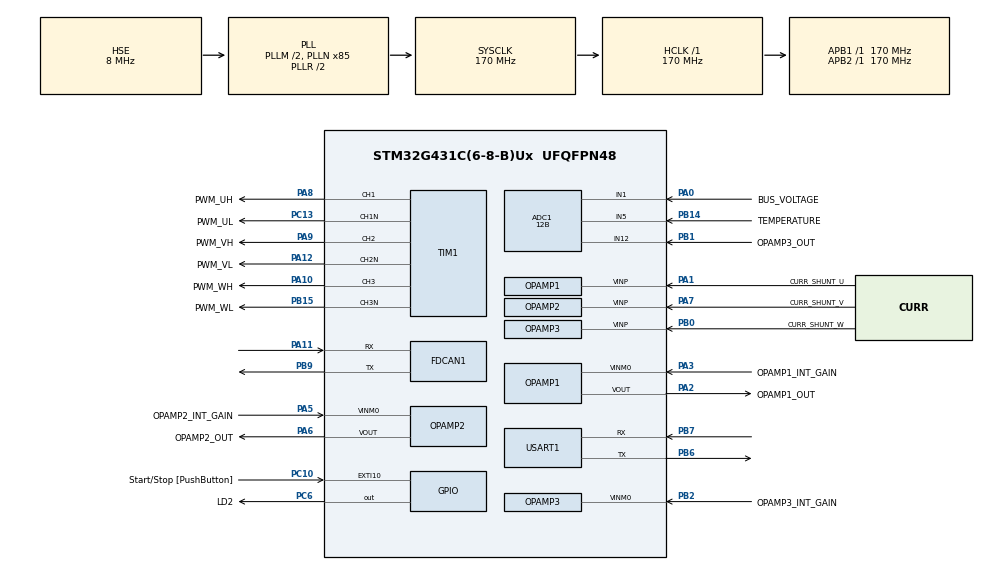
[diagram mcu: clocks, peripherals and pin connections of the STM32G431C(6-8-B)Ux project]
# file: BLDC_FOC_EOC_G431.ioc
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ADC1.Channel-1\#ChannelRegularConversion=ADC_CHANNEL_1
ADC1.Channel-2\#ChannelRegularConversion=ADC_CHANNEL_5
ADC1.ClockPrescaler=ADC_CLOCK_ASYNC_DIV1
ADC1.ContinuousConvMode=DISABLE
ADC1.DMAContinuousRequests=DISABLE
ADC1.DataAlign=ADC_DATAALIGN_LEFT
ADC1.DiscontinuousConvMode=DISABLE
ADC1.EOCSelection=ADC_EOC_SINGLE_CONV
ADC1.EnableAnalogWatchDog1=false
ADC1.EnableAnalogWatchDog2=false
ADC1.EnableAnalogWatchDog3=false
ADC1.EnableInjectedConversion=ENABLE
ADC1.EnableRegularConversion=ENABLE
ADC1.ExternalTrigConv=ADC_SOFTWARE_START
ADC1.ExternalTrigConvEdge=ADC_EXTERNALTRIGCONVEDGE_NONE
ADC1.ExternalTrigInjecConv=ADC_EXTERNALTRIGINJEC_T1_CC4
ADC1.ExternalTrigInjecConvEdge=ADC_EXTERNALTRIGINJECCONV_EDGE_RISING
ADC1.InjNumberOfConversion=2
ADC1.InjectedChannel-1\#ChannelInjectedConversion=ADC_CHANNEL_3
ADC1.InjectedChannel-2\#ChannelInjectedConversion=ADC_CHANNEL_12
ADC1.InjectedConvMode=None
ADC1.InjectedOffset-1\#ChannelInjectedConversion=0
ADC1.InjectedOffset-2\#ChannelInjectedConversion=0
ADC1.InjectedOffsetNumber-1\#ChannelInjectedConversion=ADC_OFFSET_NONE
ADC1.InjectedOffsetNumber-2\#ChannelInjectedConversion=ADC_OFFSET_NONE
ADC1.InjectedRank-1\#ChannelInjectedConversion=1
ADC1.InjectedRank-2\#ChannelInjectedConversion=2
ADC1.InjectedSamplingTime-1\#ChannelInjectedConversion=ADC_SAMPLETIME_6CYCLES_5
ADC1.InjectedSamplingTime-2\#ChannelInjectedConversion=ADC_SAMPLETIME_6CYCLES_5
ADC1.LowPowerAutoWait=DISABLE
ADC1.NbrOfConversion=2
ADC1.NbrOfConversionFlag=1
ADC1.Offset-1\#ChannelRegularConversion=0
ADC1.Offset-2\#ChannelRegularConversion=0
ADC1.OffsetNumber-1\#ChannelRegularConversion=ADC_OFFSET_NONE
ADC1.OffsetNumber-2\#ChannelRegularConversion=ADC_OFFSET_NONE
ADC1.Overrun=ADC_OVR_DATA_PRESERVED
ADC1.Rank-1\#ChannelRegularConversion=1
ADC1.Rank-2\#ChannelRegularConversion=2
ADC1.Resolution=ADC_RESOLUTION_12B
ADC1.SamplingTime-1\#ChannelRegularConversion=ADC_SAMPLETIME_47CYCLES_5
ADC1.SamplingTime-2\#ChannelRegularConversion=ADC_SAMPLETIME_47CYCLES_5
ADC1.ScanConvMode=ADC_SCAN_ENABLE
ADC1.master=1
ADC2.ClockPrescaler=ADC_CLOCK_ASYNC_DIV1
ADC2.ContinuousConvMode=DISABLE
ADC2.DMAContinuousRequests=DISABLE
ADC2.DataAlign=ADC_DATAALIGN_LEFT
ADC2.DiscontinuousConvMode=DISABLE
ADC2.EOCSelection=ADC_EOC_SINGLE_CONV
ADC2.EnableAnalogWatchDog1=false
ADC2.EnableAnalogWatchDog2=false
ADC2.EnableAnalogWatchDog3=false
ADC2.EnableInjectedConversion=ENABLE
ADC2.EnableRegularConversion=DISABLE
ADC2.ExternalTrigInjecConv=ADC_EXTERNALTRIGINJEC_T1_CC4
ADC2.ExternalTrigInjecConvEdge=ADC_EXTERNALTRIGINJECCONV_EDGE_RISING
ADC2.InjNumberOfConversion=2
ADC2.InjectedChannel-1\#ChannelInjectedConversion=ADC_CHANNEL_VOPAMP3_ADC2
ADC2.InjectedChannel-2\#ChannelInjectedConversion=ADC_CHANNEL_3
ADC2.InjectedConvMode=None
ADC2.InjectedOffset-1\#ChannelInjectedConversion=0
ADC2.InjectedOffset-2\#ChannelInjectedConversion=0
ADC2.InjectedOffsetNumber-1\#ChannelInjectedConversion=ADC_OFFSET_NONE
ADC2.InjectedOffsetNumber-2\#ChannelInjectedConversion=ADC_OFFSET_NONE
ADC2.InjectedRank-1\#ChannelInjectedConversion=1
ADC2.InjectedRank-2\#ChannelInjectedConversion=2
ADC2.InjectedSamplingTime-1\#ChannelInjectedConversion=ADC_SAMPLETIME_6CYCLES_5
ADC2.InjectedSamplingTime-2\#ChannelInjectedConversion=ADC_SAMPLETIME_6CYCLES_5
ADC2.LowPowerAutoWait=DISABLE
ADC2.Overrun=ADC_OVR_DATA_PRESERVED
ADC2.Resolution=ADC_RESOLUTION_12B
ADC2.ScanConvMode=ADC_SCAN_ENABLE
ADC2.master=1
FDCAN1.CalculateBaudRateNominal=1000000
FDCAN1.CalculateTimeBitNominal=1000
FDCAN1.CalculateTimeQuantumNominal=100.0
FDCAN1.NominalPrescaler=17
FDCAN1.NominalTimeSeg1=7
FDCAN1.NominalTimeSeg2=2
Mcu.Family=STM32G4
Mcu.Name=STM32G431C(6-8-B)Ux
Mcu.Package=UFQFPN48
NVIC.ADC1_2_IRQn=true\:2\:0\:true\:true\:false\:3\:true\:true\:true
NVIC.EXTI15_10_IRQn=true\:3\:0\:false\:true\:false\:4\:true\:true\:true
NVIC.FDCAN1_IT0_IRQn=true\:0\:0\:false\:false\:true\:true\:true\:true
NVIC.PriorityGroup=NVIC_PRIORITYGROUP_3
NVIC.TIM1_BRK_TIM15_IRQn=true\:4\:1\:true\:true\:false\:1\:true\:true\:true
NVIC.TIM1_UP_TIM16_IRQn=true\:0\:0\:false\:true\:false\:2\:true\:true\:true
NVIC.USART1_IRQn=true\:5\:0\:true\:false\:true\:true\:true\:true
OPAMP1.PgaGain=OPAMP_PGA_GAIN_16_OR_MINUS_15
OPAMP1.SelfCalibration=Disable
OPAMP2.PgaGain=OPAMP_PGA_GAIN_16_OR_MINUS_15
OPAMP2.SelfCalibration=Disable
OPAMP3.PgaGain=OPAMP_PGA_GAIN_16_OR_MINUS_15
OPAMP3.SelfCalibration=Disable
PA0.GPIO_Label=BUS_VOLTAGE
PA0.Mode=IN1-Single-Ended
PA0.Signal=ADC1_IN1
PA1.GPIO_Label=CURR_SHUNT_U
PA1.Mode=PGA Connected-INVERTINGINPUT_IO0_BIAS
PA1.Signal=OPAMP1_VINP
PA10.GPIO_Label=PWM_WH
PA10.GPIO_PuPd=GPIO_PULLDOWN
PA10.GPIO_Speed=GPIO_SPEED_FREQ_HIGH
PA10.Signal=S_TIM1_CH3
PA11.Mode=FDCAN_Activate
PA11.Signal=FDCAN1_RX
PA12.GPIO_Label=PWM_VL
PA12.GPIO_PuPd=GPIO_PULLDOWN
PA12.GPIO_Speed=GPIO_SPEED_FREQ_HIGH
PA12.Mode=PWM Generation2 CH2 CH2N
PA12.Signal=TIM1_CH2N
PA13.GPIO_Label=TMS
PA13.Mode=Serial_Wire
PA13.Signal=SYS_JTMS-SWDIO
PA14.GPIO_Label=TCK
PA14.Mode=Serial_Wire
PA14.Signal=SYS_JTCK-SWCLK
PA2.GPIO_Label=OPAMP1_OUT
PA2.Signal=SharedAnalog_PA2
PA3.GPIO_Label=OPAMP1_INT_GAIN
PA3.Mode=PGA Connected-INVERTINGINPUT_IO0_BIAS
PA3.Signal=OPAMP1_VINM0
PA5.GPIO_Label=OPAMP2_INT_GAIN
PA5.Mode=PGA Connected-INVERTINGINPUT_IO0_BIAS
PA5.Signal=OPAMP2_VINM0
PA6.GPIO_Label=OPAMP2_OUT
PA6.Signal=SharedAnalog_PA6
PA7.GPIO_Label=CURR_SHUNT_V
PA7.Mode=PGA Connected-INVERTINGINPUT_IO0_BIAS
PA7.Signal=OPAMP2_VINP
PA8.GPIO_Label=PWM_UH
PA8.GPIO_PuPd=GPIO_PULLDOWN
PA8.GPIO_Speed=GPIO_SPEED_FREQ_HIGH
PA8.Signal=S_TIM1_CH1
PA9.GPIO_Label=PWM_VH
PA9.GPIO_PuPd=GPIO_PULLDOWN
PA9.GPIO_Speed=GPIO_SPEED_FREQ_HIGH
PA9.Signal=S_TIM1_CH2
PB0.GPIO_Label=CURR_SHUNT_W
PB0.Mode=PGA Internally connected_IO0_BIAS
PB0.Signal=OPAMP3_VINP
PB1.GPIO_Label=OPAMP3_OUT
PB1.Signal=SharedAnalog_PB1
PB14.GPIO_Label=TEMPERATURE
PB14.Mode=IN5-Single-Ended
PB14.Signal=ADC1_IN5
PB15.GPIO_Label=PWM_WL
PB15.GPIO_PuPd=GPIO_PULLDOWN
PB15.GPIO_Speed=GPIO_SPEED_FREQ_HIGH
PB15.Mode=PWM Generation3 CH3 CH3N
PB15.Signal=TIM1_CH3N
PB2.GPIO_Label=OPAMP3_INT_GAIN
PB2.Mode=PGA Internally connected_IO0_BIAS
PB2.Signal=OPAMP3_VINM0
PB6.Mode=Asynchronous
PB6.Signal=USART1_TX
PB7.Mode=Asynchronous
PB7.Signal=USART1_RX
PB9.Mode=FDCAN_Activate
PB9.Signal=FDCAN1_TX
PC10.GPIO_Label=Start/Stop [PushButton]
PC10.GPIO_ModeDefaultEXTI=GPIO_MODE_IT_FALLING
PC10.GPIO_PuPd=GPIO_NOPULL
PC10.Signal=GPXTI10
PC13.GPIO_Label=PWM_UL
PC13.GPIO_PuPd=GPIO_PULLDOWN
PC13.GPIO_Speed=GPIO_SPEED_FREQ_HIGH
PC13.Mode=PWM Generation1 CH1 CH1N
PC13.Signal=TIM1_CH1N
PC6.GPIO_Label=LD2
PC6.Signal=GPIO_Output
PF0-OSC_IN.Mode=HSE-External-Oscillator
PF0-OSC_IN.Signal=RCC_OSC_IN
PF1-OSC_OUT.Mode=HSE-External-Oscillator
PF1-OSC_OUT.Signal=RCC_OSC_OUT
ProjectManager.HeapSize=0x200
ProjectManager.StackSize=0x400
ProjectManager.TargetToolchain=STM32CubeIDE
RCC.ADC12CLockSelection=RCC_ADC12CLKSOURCE_PLL
RCC.ADC12Freq_Value=42500000
RCC.AHBFreq_Value=170000000
RCC.APB1Freq_Value=170000000
RCC.APB1TimFreq_Value=170000000
RCC.APB2Freq_Value=170000000
RCC.APB2TimFreq_Value=170000000
RCC.CK48CLockSelection=RCC_USBCLKSOURCE_PLL
RCC.CortexFreq_Value=170000000
RCC.EXTERNAL_CLOCK_VALUE=12288000
RCC.EnbaleCSS=true
RCC.HCLKFreq_Value=170000000
RCC.HSE_VALUE=8000000
RCC.HSI48_VALUE=48000000
RCC.HSI_VALUE=16000000
RCC.LSE_VALUE=32768
RCC.PLLM=RCC_PLLM_DIV2
RCC.PLLN=85
RCC.PLLP=RCC_PLLP_DIV8
RCC.PLLSourceVirtual=RCC_PLLSOURCE_HSE
RCC.PREFETCH_ENABLE=1
RCC.SYSCLKFreq_VALUE=170000000
RCC.SYSCLKSource=RCC_SYSCLKSOURCE_PLLCLK
RCC.USBFreq_Value=170000000
RCC.VCOOutputFreq_Value=340000000
SH.S_TIM1_CH1.0=TIM1_CH1,PWM Generation1 CH1 CH1N
SH.S_TIM1_CH2.0=TIM1_CH2,PWM Generation2 CH2 CH2N
SH.S_TIM1_CH3.0=TIM1_CH3,PWM Generation3 CH3 CH3N
SH.SharedAnalog_PA2.0=OPAMP1_VOUT,PGA Connected-INVERTINGINPUT_IO0_BIAS
SH.SharedAnalog_PA2.1=ADC1_IN3,IN3-Single-Ended
SH.SharedAnalog_PA6.0=OPAMP2_VOUT,PGA Connected-INVERTINGINPUT_IO0_BIAS
SH.SharedAnalog_PA6.1=ADC2_IN3,IN3-Single-Ended
SH.SharedAnalog_PB1.0=OPAMP3_VOUT
SH.SharedAnalog_PB1.1=ADC1_IN12,IN12-Single-Ended
TIM1.AutoReloadPreload=TIM_AUTORELOAD_PRELOAD_DISABLE
TIM1.AutomaticOutput=TIM_AUTOMATICOUTPUT_DISABLE
TIM1.Break2Filter=3
TIM1.Break2Polarity=TIM_BREAK2POLARITY_HIGH
TIM1.Break2State=TIM_BREAK2_DISABLE
TIM1.BreakFilter=0
TIM1.BreakPolarity=TIM_BREAKPOLARITY_HIGH
TIM1.BreakState=TIM_BREAK_DISABLE
TIM1.Channel=TIM_CHANNEL_4
TIM1.Channel-PWM\ Generation1\ CH1\ CH1N=TIM_CHANNEL_1
TIM1.Channel-PWM\ Generation2\ CH2\ CH2N=TIM_CHANNEL_2
TIM1.Channel-PWM\ Generation3\ CH3\ CH3N=TIM_CHANNEL_3
TIM1.Channel-PWM\ Generation4\ No\ Output=TIM_CHANNEL_4
TIM1.ClearInputSource=TIM_CLEARINPUTSOURCE_NONE
TIM1.ClockDivision=TIM_CLOCKDIVISION_DIV2
TIM1.CounterMode=TIM_COUNTERMODE_CENTERALIGNED1
TIM1.DeadTime=((DEAD_TIME_COUNTS) / 2)
TIM1.LockLevel=TIM_LOCKLEVEL_OFF
TIM1.OC1Preload_PWM=ENABLE
TIM1.OC2Preload_PWM=ENABLE
TIM1.OC3Preload_PWM=ENABLE
TIM1.OC4Preload_PWM=ENABLE
TIM1.OCFastMode_PWM=TIM_OCFAST_DISABLE
TIM1.OCIdleState_1=TIM_OCIDLESTATE_RESET
TIM1.OCIdleState_2=TIM_OCIDLESTATE_RESET
TIM1.OCIdleState_3=TIM_OCIDLESTATE_RESET
TIM1.OCIdleState_4=TIM_OCIDLESTATE_RESET
TIM1.OCMode_PWM-PWM\ Generation1\ CH1\ CH1N=TIM_OCMODE_PWM1
TIM1.OCMode_PWM-PWM\ Generation2\ CH2\ CH2N=TIM_OCMODE_PWM1
TIM1.OCMode_PWM-PWM\ Generation3\ CH3\ CH3N=TIM_OCMODE_PWM1
TIM1.OCMode_PWM-PWM\ Generation4\ No\ Output=TIM_OCMODE_PWM2
TIM1.OCNIdleState_1=TIM_OCNIDLESTATE_RESET
TIM1.OCNIdleState_2=TIM_OCNIDLESTATE_RESET
TIM1.OCNIdleState_3=TIM_OCNIDLESTATE_RESET
TIM1.OCNPolarity_1=TIM_OCNPOLARITY_HIGH
TIM1.OCNPolarity_2=TIM_OCNPOLARITY_HIGH
TIM1.OCNPolarity_3=TIM_OCNPOLARITY_HIGH
TIM1.OCPolarity_1=TIM_OCPOLARITY_HIGH
TIM1.OCPolarity_2=TIM_OCPOLARITY_HIGH
TIM1.OCPolarity_3=TIM_OCPOLARITY_HIGH
TIM1.OCPolarity_4=TIM_OCPOLARITY_HIGH
TIM1.OffStateIDLEMode=TIM_OSSI_ENABLE
TIM1.OffStateRunMode=TIM_OSSR_ENABLE
TIM1.PeriodNoDither=((PWM_PERIOD_CYCLES) / 2)
TIM1.Prescaler=((TIM_CLOCK_DIVIDER) - 1)
TIM1.PulseNoDither_1=((PWM_PERIOD_CYCLES) / 4)
TIM1.PulseNoDither_2=((PWM_PERIOD_CYCLES) / 4)
TIM1.PulseNoDither_3=((PWM_PERIOD_CYCLES) / 4)
TIM1.PulseNoDither_4=(((PWM_PERIOD_CYCLES) / 2) - (HTMIN))
TIM1.RepetitionCounter=(REP_COUNTER)
TIM1.SourceBRK2DigInput=TIM_BREAKINPUTSOURCE_DISABLE
TIM1.SourceBRKDigInput=TIM_BREAKINPUTSOURCE_DISABLE
TIM1.TIM_MasterOutputTrigger=TIM_TRGO_OC4REF
TIM1.TIM_MasterOutputTrigger2=TIM_TRGO2_RESET
TIM1.TIM_MasterSlaveMode=TIM_MASTERSLAVEMODE_DISABLE
TIM1.TIM_SlaveMode=TIM_SLAVEMODE_TRIGGER
USART1.VirtualMode-Asynchronous=VM_ASYNC
VP_ADC2_OPAMP_INTERNAL3.Mode=IN-OPAMP3
VP_CORDIC_VS_CORDIC.Mode=CORDIC_Activate
VP_SYS_VS_DBSignals.Mode=DisableDeadBatterySignals
VP_TIM1_VS_no_output4.Mode=PWM Generation4 No Output
board=custom

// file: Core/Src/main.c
/* USER CODE BEGIN Header */
/**
  ******************************************************************************
  * @file           : main.c
  * @brief          : Main program body
  ******************************************************************************
  * @attention
  *
  * Copyright (c) 2026 STMicroelectronics.
  * All rights reserved.
  *
  * This software is licensed under terms that can be found in the LICENSE file
  * in the root directory of this software component.
  * If no LICENSE file comes with this software, it is provided AS-IS.
  *
  ******************************************************************************
  */
/* USER CODE END Header */
#include "main.h"
#include "adc.h"
#include "cordic.h"
#include "fdcan.h"
#include "opamp.h"
#include "tim.h"
#include "usart.h"
#include "gpio.h"

/* USER CODE BEGIN PD */
#define M1_ENC_IC_FILTER 	1
#define DEAD_TIME_COUNTS 	1
#define M1_PULSE_NBR	 	1
#define HTMIN			 	1
#define REP_COUNTER		 	1
#define PWM_PERIOD_CYCLES	1
#define TIM_CLOCK_DIVIDER	1
/* USER CODE END PD */

void SystemClock_Config(void);
static void MX_NVIC_Init(void);

int main(void)
{

  /* MCU Configuration--------------------------------------------------------*/

  /* Reset of all peripherals, Initializes the Flash interface and the Systick. */
  HAL_Init();

  /* Configure the system clock */
  SystemClock_Config();

  /* Initialize all configured peripherals */
  MX_GPIO_Init();
  MX_ADC1_Init();
  MX_ADC2_Init();
  MX_CORDIC_Init();
  MX_OPAMP1_Init();
  MX_OPAMP2_Init();
  MX_OPAMP3_Init();
  MX_TIM1_Init();
  MX_FDCAN1_Init();
  MX_USART1_UART_Init();

  /* Initialize interrupts */
  MX_NVIC_Init();

  /* Infinite loop */
  while (1)
  {

  }
}

void SystemClock_Config(void)
{
  RCC_OscInitTypeDef RCC_OscInitStruct = {0};
  RCC_ClkInitTypeDef RCC_ClkInitStruct = {0};

  /** Configure the main internal regulator output voltage
  */
  HAL_PWREx_ControlVoltageScaling(PWR_REGULATOR_VOLTAGE_SCALE1_BOOST);

  /** Initializes the RCC Oscillators according to the specified parameters
  * in the RCC_OscInitTypeDef structure.
  */
  RCC_OscInitStruct.OscillatorType = RCC_OSCILLATORTYPE_HSE;
  RCC_OscInitStruct.HSEState = RCC_HSE_ON;
  RCC_OscInitStruct.PLL.PLLState = RCC_PLL_ON;
  RCC_OscInitStruct.PLL.PLLSource = RCC_PLLSOURCE_HSE;
  RCC_OscInitStruct.PLL.PLLM = RCC_PLLM_DIV2;
  RCC_OscInitStruct.PLL.PLLN = 85;
  RCC_OscInitStruct.PLL.PLLP = RCC_PLLP_DIV8;
  RCC_OscInitStruct.PLL.PLLQ = RCC_PLLQ_DIV2;
  RCC_OscInitStruct.PLL.PLLR = RCC_PLLR_DIV2;
  if (HAL_RCC_OscConfig(&RCC_OscInitStruct) != HAL_OK)
  {
    Error_Handler();
  }

  /** Initializes the CPU, AHB and APB buses clocks
  */
  RCC_ClkInitStruct.ClockType = RCC_CLOCKTYPE_HCLK|RCC_CLOCKTYPE_SYSCLK
                              |RCC_CLOCKTYPE_PCLK1|RCC_CLOCKTYPE_PCLK2;
  RCC_ClkInitStruct.SYSCLKSource = RCC_SYSCLKSOURCE_PLLCLK;
  RCC_ClkInitStruct.AHBCLKDivider = RCC_SYSCLK_DIV1;
  RCC_ClkInitStruct.APB1CLKDivider = RCC_HCLK_DIV1;
  RCC_ClkInitStruct.APB2CLKDivider = RCC_HCLK_DIV1;

  if (HAL_RCC_ClockConfig(&RCC_ClkInitStruct, FLASH_LATENCY_4) != HAL_OK)
  {
    Error_Handler();
  }

  /** Enables the Clock Security System
  */
  HAL_RCC_EnableCSS();
}

/**
  * @brief NVIC Configuration.
  * @retval None
  */
static void MX_NVIC_Init(void)
{
  /* TIM1_BRK_TIM15_IRQn interrupt configuration */
  HAL_NVIC_SetPriority(TIM1_BRK_TIM15_IRQn, 4, 1);
  HAL_NVIC_EnableIRQ(TIM1_BRK_TIM15_IRQn);
  /* TIM1_UP_TIM16_IRQn interrupt configuration */
  HAL_NVIC_SetPriority(TIM1_UP_TIM16_IRQn, 0, 0);
  HAL_NVIC_EnableIRQ(TIM1_UP_TIM16_IRQn);
  /* ADC1_2_IRQn interrupt configuration */
  HAL_NVIC_SetPriority(ADC1_2_IRQn, 2, 0);
  HAL_NVIC_EnableIRQ(ADC1_2_IRQn);
  /* EXTI15_10_IRQn interrupt configuration */
  HAL_NVIC_SetPriority(EXTI15_10_IRQn, 3, 0);
  HAL_NVIC_EnableIRQ(EXTI15_10_IRQn);
}

void Error_Handler(void)
{
  __disable_irq();
  while (1)
  {
  }
}
